# MSP430FR2433 register map
Registers are 16-bit, read-write, reset 0x0 unless marked. A register's access mark holds for its fields unless they carry their own. Offsets are from the block's base; [hi:lo] are bit positions; {n}, {i} and the like mark numbered series.

## PMM — PMM Power Management System
Base 0x00000120
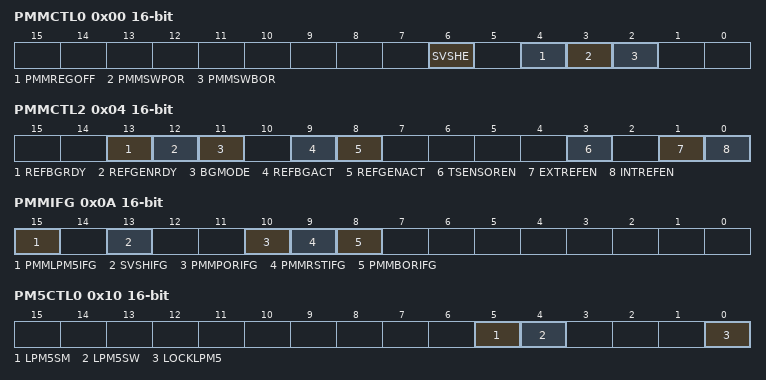
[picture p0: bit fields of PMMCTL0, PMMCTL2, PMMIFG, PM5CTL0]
0x00 PMMCTL0 — PMM Control 0
  [6] SVSHE — SVS high side enable
  [4] PMMREGOFF — PMM Turn Regulator off
  [3] PMMSWPOR — PMM Software POR
  [2] PMMSWBOR — PMM Software BOR
0x02 PMMCTL1 — PMM Control 1
0x04 PMMCTL2 — PMM Control 2
  [13] REFBGRDY — REF Reference bandgap ready
  [12] REFGENRDY — REF Reference generator ready
  [11] BGMODE — REF Bandgap mode
  [9] REFBGACT — REF Reference bandgap active
  [8] REFGENACT — REF Reference generator active
  [3] TSENSOREN — Temperature Sensor Enable
  [1] EXTREFEN — External Reference output Enable
  [0] INTREFEN — Internal Reference Enable
0x0A PMMIFG — PMM Interrupt Flag
  [15] PMMLPM5IFG — LPM5 indication Flag
  [13] SVSHIFG — SVS low side interrupt flag
  [10] PMMPORIFG — PMM Software POR interrupt flag
  [9] PMMRSTIFG — PMM RESET pin interrupt flag
  [8] PMMBORIFG — PMM Software BOR interrupt flag
0x0E PMMIE — PMM Interrupt Enable
0x10 PM5CTL0 — PMM Power Mode 5 Control Register 0
  [5] LPM5SM — Manual mode for LPM3.5 switch
  [4] LPM5SW — LPMx.5 switch dis/connected
  [0] LOCKLPM5 — Lock I/O pin configuration upon entry/exit to/from LPM5

## SYS — SYS System Module
Base 0x00000140
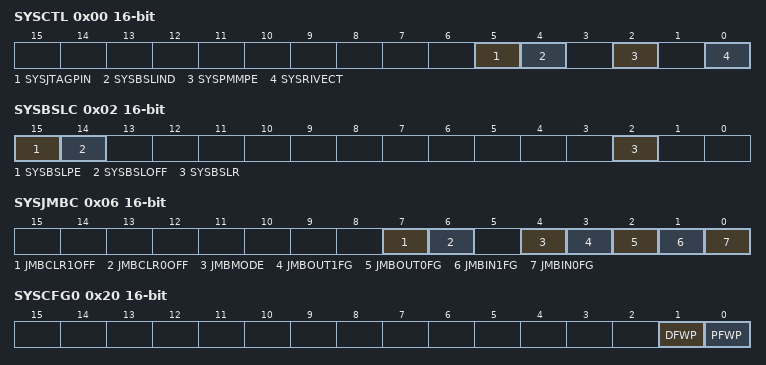
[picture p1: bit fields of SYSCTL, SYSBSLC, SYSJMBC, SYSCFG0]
0x00 SYSCTL — System control
  [5] SYSJTAGPIN — SYS - Dedicated JTAG pins enabled
  [4] SYSBSLIND — SYS - TCK/RST indication detected
  [2] SYSPMMPE — SYS - PMM access protect
  [0] SYSRIVECT — SYS - RAM based interrupt vectors
0x02 SYSBSLC — Boot strap configuration area
  [15] SYSBSLPE — SYS - BSL Memory protection enabled
  [14] SYSBSLOFF — SYS - BSL Memory disabled
  [2] SYSBSLR — SYS - RAM assigned to BSL
0x06 SYSJMBC — JTAG mailbox control
  [7] JMBCLR1OFF — SYS - Incoming JTAG Mailbox 1 Flag auto-clear disalbe
  [6] JMBCLR0OFF — SYS - Incoming JTAG Mailbox 0 Flag auto-clear disalbe
  [4] JMBMODE — SYS - JMB 16/32 Bit Mode
  [3] JMBOUT1FG — SYS - Outgoing JTAG Mailbox 1 Flag
  [2] JMBOUT0FG — SYS - Outgoing JTAG Mailbox 0 Flag
  [1] JMBIN1FG — SYS - Incoming JTAG Mailbox 1 Flag
  [0] JMBIN0FG — SYS - Incoming JTAG Mailbox 0 Flag
0x08 SYSJMBI0 — JTAG mailbox input 0
0x0A SYSJMBI1 — JTAG mailbox input 1
0x0C SYSJMBO0 — JTAG mailbox output 0
0x0E SYSJMBO1 — JTAG mailbox output 1
0x18 SYSBERRIV — Bus Error vector generator
0x1A SYSUNIV — User NMI vector generator
0x1C SYSSNIV — System NMI vector generator
0x1E SYSRSTIV — Reset vector generator
0x20 SYSCFG0 — System Configuration 0
  [1] DFWP — Data FRAM Write Protection
  [0] PFWP — Program FRAM Write Protection
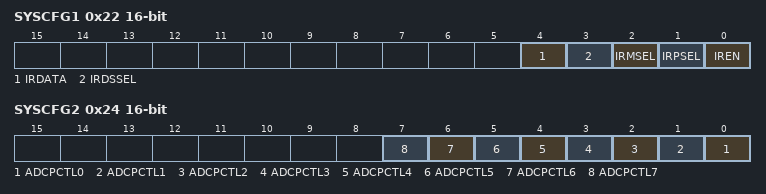
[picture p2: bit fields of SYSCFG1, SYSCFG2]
0x22 SYSCFG1 — System Configuration 1
  [4] IRDATA — Infrared enable
  [3] IRDSSEL — Infrared data source select
  [2] IRMSEL — Infrared mode select
  [1] IRPSEL — Infrared polarity select
  [0] IREN — Infrared enable
0x24 SYSCFG2 — System Configuration 2
  [n] ADCPCTL{n} (n=0..7) — ADC input A{n} pin select

## CS — CS Clock System
Base 0x00000180
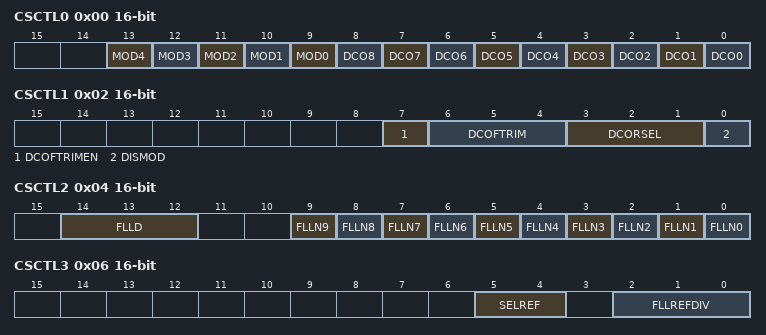
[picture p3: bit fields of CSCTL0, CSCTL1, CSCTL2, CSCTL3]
0x00 CSCTL0 — CS Control Register 0
  [n+9] MOD{n} (n=0..4) — Modulation Bit Counter Bit : {n}
  [n] DCO{n} (n=0..8) — DCO TAP Bit : {n}
0x02 CSCTL1 — CS Control Register 1
  [7] DCOFTRIMEN — DCO frequency trim enable
  [6:4] DCOFTRIM — DCO frequency trim. Bit: 0
    {v}=DCO frequency trim: {v} (v=0..7)
  [3:1] DCORSEL — DCO frequency range select Bit: 0
    {v}=DCO frequency range select: {v} (v=0..7)
  [0] DISMOD — Disable Modulation
0x04 CSCTL2 — CS Control Register 2
  [14:12] FLLD — Loop Divider Bit : 0
    0=Multiply Selected Loop Freq. By 1; 1=Multiply Selected Loop Freq. By 2; 2=Multiply Selected Loop Freq. By 4; 3=Multiply Selected Loop Freq. By 8; 4=Multiply Selected Loop Freq. By 16; 5=Multiply Selected Loop Freq. By 32
  [n] FLLN{n} (n=0..9) — FLL Multipier Bit : {n}
0x06 CSCTL3 — CS Control Register 3
  [5:4] SELREF — FLL Reference Clock Select Bit : 0
    {v}=FLL Reference Clock Select {v} (v=0..3)
  [2:0] FLLREFDIV — Reference Divider Bit : 0
    0=Reference Divider: f(LFCLK)/1; 1=Reference Divider: f(LFCLK)/2; 2=Reference Divider: f(LFCLK)/4; 3=Reference Divider: f(LFCLK)/8; 4=Reference Divider: f(LFCLK)/12; 5=Reference Divider: f(LFCLK)/16; 6=Reference Divider: f(LFCLK)/16; 7=Reference Divider: f(LFCLK)/16
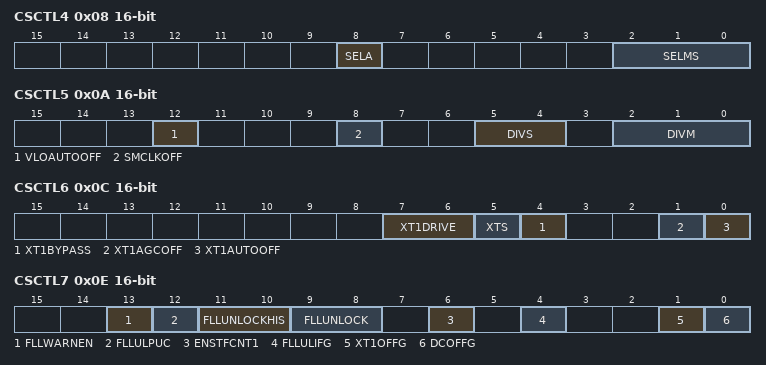
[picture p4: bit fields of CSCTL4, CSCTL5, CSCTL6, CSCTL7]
0x08 CSCTL4 — CS Control Register 4
  [8] SELA — ACLK Source Select Bit: 0
  [2:0] SELMS — MCLK and SMCLK Source Select Bit: 0
    {v}=MCLK and SMCLK Source Select {v} (v=0..7)
0x0A CSCTL5 — CS Control Register 5
  [12] VLOAUTOOFF — VLO automatic off enable
  [8] SMCLKOFF
  [5:4] DIVS — SMCLK Divider Bit: 0
    {v}=SMCLK Source Divider {v} (v=0..3)
  [2:0] DIVM — MCLK Divider Bit: 0
    {v}=MCLK Source Divider {v} (v=0..7)
0x0C CSCTL6 — CS Control Register 6
  [7:6] XT1DRIVE — XT1 Drive Level mode Bit 0
    {v}=XT1 Drive Level mode: {v} (v=0..3)
  [5] XTS — 1: Selects high-freq. oscillator
  [4] XT1BYPASS — XT1 bypass mode : 0: internal 1:sourced from external pin
  [1] XT1AGCOFF — XT1 Automatic Gain Control (AGC) disable
  [0] XT1AUTOOFF — XT1 automatic off enable
0x0E CSCTL7 — CS Control Register 7
  [13] FLLWARNEN — Warning enable
  [12] FLLULPUC — FLL unlock PUC enable
  [11:10] FLLUNLOCKHIS — Unlock history Bit: 0
    {v}=Unlock history: {v} (v=0..3)
  [9:8] FLLUNLOCK — FLL unlock condition Bit: 0
    {v}=FLL unlock condition: {v} (v=0..3)
  [6] ENSTFCNT1 — Enable start counter for XT1
  [4] FLLULIFG — FLL unlock interrupt flag
  [1] XT1OFFG — XT1 Low Frequency Oscillator Fault Flag
  [0] DCOFFG — DCO fault flag
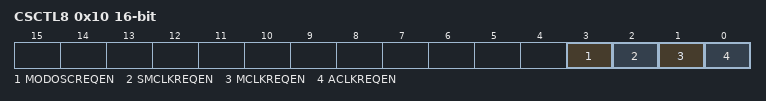
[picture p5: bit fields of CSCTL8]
0x10 CSCTL8 — CS Control Register 8
  [3] MODOSCREQEN — MODOSC Clock Request Enable
  [2] SMCLKREQEN — SMCLK Clock Request Enable
  [1] MCLKREQEN — MCLK Clock Request Enable
  [0] ACLKREQEN — ACLK Clock Request Enable
